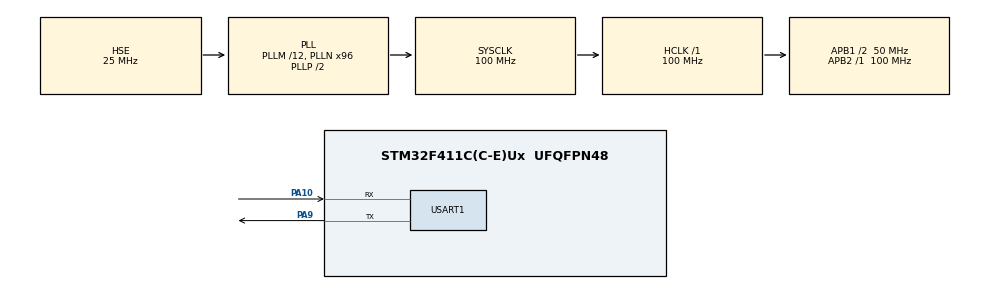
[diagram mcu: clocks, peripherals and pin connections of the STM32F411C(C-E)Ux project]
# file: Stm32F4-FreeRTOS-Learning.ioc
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FREERTOS.Tasks01=defaultTask,24,128,StartDefaultTask,Default,NULL,Dynamic,NULL,NULL
Mcu.Family=STM32F4
Mcu.Name=STM32F411C(C-E)Ux
Mcu.Package=UFQFPN48
NVIC.PriorityGroup=NVIC_PRIORITYGROUP_4
PA10.Mode=Asynchronous
PA10.Signal=USART1_RX
PA13.Mode=Serial_Wire
PA13.Signal=SYS_JTMS-SWDIO
PA14.Mode=Serial_Wire
PA14.Signal=SYS_JTCK-SWCLK
PA9.Mode=Asynchronous
PA9.Signal=USART1_TX
PC14-OSC32_IN.Mode=LSE-External-Oscillator
PC14-OSC32_IN.Signal=RCC_OSC32_IN
PC15-OSC32_OUT.Mode=LSE-External-Oscillator
PC15-OSC32_OUT.Signal=RCC_OSC32_OUT
PH0\ -\ OSC_IN.Mode=HSE-External-Oscillator
PH0\ -\ OSC_IN.Signal=RCC_OSC_IN
PH1\ -\ OSC_OUT.Mode=HSE-External-Oscillator
PH1\ -\ OSC_OUT.Signal=RCC_OSC_OUT
ProjectManager.HeapSize=0x200
ProjectManager.StackSize=0x400
ProjectManager.TargetToolchain=MDK-ARM V5.32
RCC.48MHZClocksFreq_Value=50000000
RCC.AHBFreq_Value=100000000
RCC.APB1CLKDivider=RCC_HCLK_DIV2
RCC.APB1Freq_Value=50000000
RCC.APB1TimFreq_Value=100000000
RCC.APB2Freq_Value=100000000
RCC.APB2TimFreq_Value=100000000
RCC.CortexFreq_Value=100000000
RCC.HCLKFreq_Value=100000000
RCC.HSE_VALUE=25000000
RCC.HSI_VALUE=16000000
RCC.PLLM=12
RCC.PLLN=96
RCC.PLLSourceVirtual=RCC_PLLSOURCE_HSE
RCC.SYSCLKFreq_VALUE=100000000
RCC.SYSCLKSource=RCC_SYSCLKSOURCE_PLLCLK
RCC.VCOOutputFreq_Value=200000000
USART1.VirtualMode=VM_ASYNC
VP_FREERTOS_VS_CMSIS_V2.Mode=CMSIS_V2
board=custom

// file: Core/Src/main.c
/* USER CODE BEGIN Header */
/**
  ******************************************************************************
  * @file           : main.c
  * @brief          : Main program body
  ******************************************************************************
  * @attention
  *
  * Copyright (c) 2026 STMicroelectronics.
  * All rights reserved.
  *
  * This software is licensed under terms that can be found in the LICENSE file
  * in the root directory of this software component.
  * If no LICENSE file comes with this software, it is provided AS-IS.
  *
  ******************************************************************************
  */
/* USER CODE END Header */
#include "main.h"
#include "cmsis_os.h"
#include "usart.h"
#include "gpio.h"

void SystemClock_Config(void);
void MX_FREERTOS_Init(void);

int main(void)
{

  /* MCU Configuration--------------------------------------------------------*/

  /* Reset of all peripherals, Initializes the Flash interface and the Systick. */
  HAL_Init();

  /* Configure the system clock */
  SystemClock_Config();

  /* Initialize all configured peripherals */
  MX_GPIO_Init();
  MX_USART1_UART_Init();

  /* Init scheduler */
  osKernelInitialize();  /* Call init function for freertos objects (in freertos.c) */

    uart_mutex = xSemaphoreCreateMutex();

  MX_FREERTOS_Init();

  /* Start scheduler */
  osKernelStart();
  /* We should never get here as control is now taken by the scheduler */
  /* Infinite loop */
  while (1)
  {

  }
}

void SystemClock_Config(void)
{
  RCC_OscInitTypeDef RCC_OscInitStruct = {0};
  RCC_ClkInitTypeDef RCC_ClkInitStruct = {0};

  /** Configure the main internal regulator output voltage
  */
  __HAL_RCC_PWR_CLK_ENABLE();
  __HAL_PWR_VOLTAGESCALING_CONFIG(PWR_REGULATOR_VOLTAGE_SCALE1);

  /** Initializes the RCC Oscillators according to the specified parameters
  * in the RCC_OscInitTypeDef structure.
  */
  RCC_OscInitStruct.OscillatorType = RCC_OSCILLATORTYPE_HSE;
  RCC_OscInitStruct.HSEState = RCC_HSE_ON;
  RCC_OscInitStruct.PLL.PLLState = RCC_PLL_ON;
  RCC_OscInitStruct.PLL.PLLSource = RCC_PLLSOURCE_HSE;
  RCC_OscInitStruct.PLL.PLLM = 12;
  RCC_OscInitStruct.PLL.PLLN = 96;
  RCC_OscInitStruct.PLL.PLLP = RCC_PLLP_DIV2;
  RCC_OscInitStruct.PLL.PLLQ = 4;
  if (HAL_RCC_OscConfig(&RCC_OscInitStruct) != HAL_OK)
  {
    Error_Handler();
  }

  /** Initializes the CPU, AHB and APB buses clocks
  */
  RCC_ClkInitStruct.ClockType = RCC_CLOCKTYPE_HCLK|RCC_CLOCKTYPE_SYSCLK
                              |RCC_CLOCKTYPE_PCLK1|RCC_CLOCKTYPE_PCLK2;
  RCC_ClkInitStruct.SYSCLKSource = RCC_SYSCLKSOURCE_PLLCLK;
  RCC_ClkInitStruct.AHBCLKDivider = RCC_SYSCLK_DIV1;
  RCC_ClkInitStruct.APB1CLKDivider = RCC_HCLK_DIV2;
  RCC_ClkInitStruct.APB2CLKDivider = RCC_HCLK_DIV1;

  if (HAL_RCC_ClockConfig(&RCC_ClkInitStruct, FLASH_LATENCY_3) != HAL_OK)
  {
    Error_Handler();
  }
}

void HAL_TIM_PeriodElapsedCallback(TIM_HandleTypeDef *htim)
{
  if (htim->Instance == TIM1) {
    HAL_IncTick();
  }
}

void Error_Handler(void)
{
  __disable_irq();
  while (1)
  {
  }
}

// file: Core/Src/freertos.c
/* USER CODE BEGIN Header */
/**
  ******************************************************************************
  * File Name          : freertos.c
  * Description        : Code for freertos applications
  ******************************************************************************
  * @attention
  *
  * Copyright (c) 2026 STMicroelectronics.
  * All rights reserved.
  *
  * This software is licensed under terms that can be found in the LICENSE file
  * in the root directory of this software component.
  * If no LICENSE file comes with this software, it is provided AS-IS.
  *
  ******************************************************************************
  */
/* USER CODE END Header */

#include "FreeRTOS.h"
#include "task.h"
#include "main.h"
#include "cmsis_os.h"

/* USER CODE BEGIN Includes */
#include "queue.h"
#include "semphr.h"
#include <stdint.h>

#include "KeyLedStateMachine.h"

/* USER CODE END Includes */

/* USER CODE BEGIN Variables */
QueueHandle_t queue_key_led = NULL ;
/* USER CODE END Variables */
/* Definitions for defaultTask */
osThreadId_t defaultTaskHandle;
const osThreadAttr_t defaultTask_attributes = {
  .name = "defaultTask",
  .stack_size = 128 * 4,
  .priority = (osPriority_t) osPriorityNormal,
};

/* USER CODE BEGIN FunctionPrototypes */

void KeyTask( void  );
void LedTask( void  );

/* USER CODE END FunctionPrototypes */

void StartDefaultTask(void *argument);

void MX_FREERTOS_Init(void); /* (MISRA C 2004 rule 8.1) */

void MX_FREERTOS_Init(void) {

  /* USER CODE BEGIN RTOS_QUEUES */
    // communicate between led and key
    queue_key_led = xQueueCreate( (UBaseType_t)10, sizeof(uint8_t) );
    if( NULL == queue_key_led )
    {
        printf(" queue_key_led queue create FAIL! \n ");
    }

  /* USER CODE END RTOS_QUEUES */

  /* Create the thread(s) */
  /* creation of defaultTask */
  defaultTaskHandle = osThreadNew(StartDefaultTask, NULL, &defaultTask_attributes);

  /* USER CODE BEGIN RTOS_THREADS */
  /* add threads, ... */
    // create tasks
    BaseType_t  key = xTaskCreate( KeyTask,
                                    " Key control LED ",
                                    1000,
                                    NULL,
                                    1,
                                    NULL );
    if(  pdPASS == key )
    {
        printf("KeyTask create SUCCESS! \n");
    }
    else{
        printf("KeyTask create FAIL! \n");
    }

    BaseType_t Led = xTaskCreate( LedTask,
                                    " LED flash ",
                                    1000,
                                    NULL,
                                    1,
                                    NULL );
    if(  pdPASS == Led )
    {
        printf("LedTask create SUCCESS! \n");
    }
    else{
        printf("LedTask create FAIL! \n");
    }

  /* USER CODE END RTOS_THREADS */

}

void StartDefaultTask(void *argument)
{
  /* USER CODE BEGIN StartDefaultTask */
  /* Infinite loop */
  for(;;)
  {

        vTaskDelay(500);
  }
  /* USER CODE END StartDefaultTask */
}

/* USER CODE BEGIN Application */

/**
 * @brief Key check function
 *
 */
void KeyTask( void  )
{
    for(;;)
    {
        // 获取
        keyState_t key_status = eKEY_IDLE;
        GPIO_PinState key_state = HAL_GPIO_ReadPin(KEY_GPIO_Port,  KEY_Pin );

        static uint32_t delay_ms = 0 ;

        switch ( key_state )
        {
            case GPIO_PIN_RESET:
                key_status = eKEY_DOWN ;
                vTaskDelay(10);
                delay_ms = delay_ms + 10 ;

                if( delay_ms < 1000 )
                {
                    if( HAL_GPIO_ReadPin(KEY_GPIO_Port, KEY_Pin) == GPIO_PIN_RESET )
                    {
                        break;      // 这里还不太明白，似乎是因为偶发性重合，延时后不一定高电平，// 机械抖动或者是按的时间长强制等到高电平，需要回看第一节
                    }
                    else
                    {
                        key_status = eKEY_FINISH ;
                        printf("KeyTask KEY_FINISH delay_ms is  %d \n", key_status);
                        xQueueSendToBack(queue_key_led, (uint8_t *)&key_status, 10  );
                        delay_ms = 0;
                        break ;
                    }

                }
                else
                {
                    key_status = eKEY_LONGPRESS ;
                    printf("KeyTask KEY_LONGPRESS delay_ms is  %d \n", key_status);
                    xQueueSendToBack(queue_key_led, (uint8_t *)&key_status, 10  );
                    delay_ms = 0;
                }
                printf("KeyTask is running! \n");
                break;
            case GPIO_PIN_SET:
                key_status = eKEY_UP ;
                xQueueSendToBack(queue_key_led, (uint8_t *)&key_status, 10  );
                break;

            default:
                break;
        }

    }
}

/**
 * @brief LED  flash function
 *
 */
void LedTask( void  )
{
    for(;;)
    {
        BaseType_t led_status  =  0 ;
        keyState_t key_status = eKEY_IDLE ;     // 这里的指针似乎有问题
        led_status = xQueueReceive( queue_key_led, &key_status, 100 );
        if( led_status != pdPASS )
        {
            printf(" Could not Receive data from KEY !\n");
            // 在没有收到的时候会一直打印信息
        }
        // printf("LEDTASK is running! \n");
        switch( key_status )
        {
            case eKEY_DOWN:

                break;
            case eKEY_UP:

                break;
            case eKEY_FINISH :
                    vTaskDelay(pdMS_TO_TICKS(50));          //  test bug
                    printf("LedTask is running! \n");       // 为什么不打印？
                    HAL_GPIO_TogglePin( LED_GPIO_Port ,  LED_Pin);
                break;
            case eKEY_LONGPRESS :
                    GPIO_PinState led_old_state = 0;
                    // led_old_state = HAL_GPIO_ReadPin( LED_GPIO_Port ,  LED_Pin );
                    // printf("KEY_LONGPRESS LedTask is %d! \n", led_old_state);
                    LedToggleSeveralTimes(3);
                    // HAL_GPIO_WritePin( LED_GPIO_Port ,  LED_Pin , led_old_state) ;
                    // printf("KEY_LONGPRESS LedTask is %d! \n", led_old_state);
                break ;
            default:
                break;

        }

    }
}

/* USER CODE END Application */
